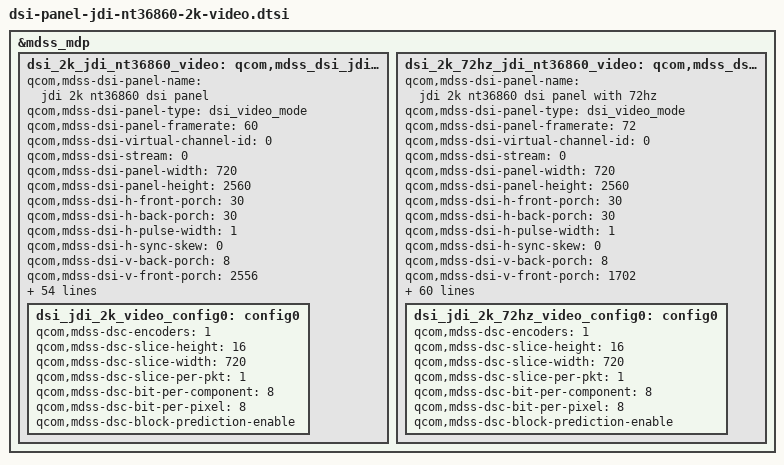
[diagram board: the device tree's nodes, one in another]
/* Copyright (c) 2017, Oculus VR.  All rights reserved.
 *
 * This program is free software; you can redistribute it and/or modify
 * it under the terms of the GNU General Public License version 2 and
 * only version 2 as published by the Free Software Foundation.
 *
 * This program is distributed in the hope that it will be useful,
 * but WITHOUT ANY WARRANTY; without even the implied warranty of
 * MERCHANTABILITY or FITNESS FOR A PARTICULAR PURPOSE.  See the
 * GNU General Public License for more details.
 */

&mdss_mdp {
	dsi_2k_jdi_nt36860_video: qcom,mdss_dsi_jdi_2k_nt36860_video {
		qcom,mdss-dsi-panel-name = "jdi 2k nt36860 dsi panel";
		qcom,mdss-dsi-panel-type = "dsi_video_mode";
		qcom,mdss-dsi-panel-framerate = <60>;
		qcom,mdss-dsi-virtual-channel-id = <0>;
		qcom,mdss-dsi-stream = <0>;
		qcom,mdss-dsi-panel-width = <720>;
		qcom,mdss-dsi-panel-height = <2560>;
		qcom,mdss-dsi-h-front-porch = <30>;
		qcom,mdss-dsi-h-back-porch = <30>;
		qcom,mdss-dsi-h-pulse-width = <1>;
		qcom,mdss-dsi-h-sync-skew = <0>;
		qcom,mdss-dsi-v-back-porch = <8>;
		qcom,mdss-dsi-v-front-porch = <2556>;
		qcom,mdss-dsi-v-pulse-width = <2>;
		qcom,mdss-dsi-bpp = <24>;
		qcom,mdss-dsi-border-color = <0>;
		qcom,mdss-dsi-on-command-state = "dsi_lp_mode";
		qcom,mdss-dsi-off-command-state = "dsi_hs_mode";
		qcom,mdss-dsi-h-sync-pulse = <0>;
		qcom,mdss-dsi-traffic-mode = "burst_mode";
		qcom,mdss-dsi-bllp-eof-power-mode;
		qcom,mdss-dsi-bllp-power-mode;
		qcom,mdss-dsi-lane-0-state;
		qcom,mdss-dsi-lane-1-state;
		qcom,mdss-dsi-lane-2-state;
		qcom,mdss-dsi-lane-3-state;
		qcom,mdss-dsi-panel-timings = [
			94 20 14 00 46 4a 1a 24 18 03 04 00
		];
		qcom,mdss-dsi-t-clk-post = <0xd>;
		qcom,mdss-dsi-t-clk-pre = <0x2e>;
		qcom,mdss-dsi-dma-trigger = "trigger_sw";
		qcom,mdss-dsi-mdp-trigger = "none";
		qcom,mdss-dsi-reset-sequence = <0 10>, <1 20>, <0 20>, <1 20>;
		qcom,mdss-dsi-te-pin-select = <1>;
		qcom,mdss-dsi-wr-mem-start = <0x2c>;
		qcom,mdss-dsi-wr-mem-continue = <0x3c>;
		qcom,mdss-dsi-te-dcs-command = <1>;
		qcom,mdss-dsi-te-check-enable;
		qcom,mdss-dsi-te-using-te-pin;
		qcom,ulps-enabled;
		qcom,dcs-cmd-by-left;
		qcom,mdss-dsi-tx-eot-append;
		qcom,mdss-pan-physical-width-dimension = <68>;
		qcom,mdss-pan-physical-height-dimension = <121>;

		qcom,mdss-dsi-panel-hdr-enabled;
		// Scale by 1 / 50000 to get x & y coordinates
		qcom,mdss-dsi-panel-hdr-color-primaries = <
			14700 15700 // W - x: 0.294, y: 0.314
			32000 16600 // R - x: 0.640, y: 0.332
			15000 30000 // G - x: 0.300. y: 0.600
			7700 3000>; // B - x: 0.154, y: 0.060
		// Scale by 1 / 10000 to get nits
		qcom,mdss-dsi-panel-peak-brightness = <1000000>;
		qcom,mdss-dsi-panel-blackness-level = <1400>;

		// Default to 10% base DC
		oculus,bklt-duty-cycle-numerator = <1000>;
		oculus,bklt-duty-cycle-denominator = <10000>;

		qcom,adjust-timer-wakeup-ms = <1>;
		qcom,mdss-dsi-panel-status-command = [
			06 01 00 01 05 00 02 0A 08
		];
		qcom,mdss-dsi-panel-status-command-state = "dsi_hs_mode";
		qcom,mdss-dsi-panel-status-check-mode = "reg_read";
		qcom,mdss-dsi-panel-status-value = <0x9c>;
		/*qcom,esd-check-enabled;*/
		qcom,mdss-dsi-panel-status-read-length=<1>;
		qcom,mdss-dsi-on-command = [
			15 01 00 00 00 00 02 ff 10
			15 01 00 00 00 00 02 fb 01
			39 01 00 00 00 00 05 2a 00 00 05 9f
			39 01 00 00 00 00 05 2b 00 00 09 ff
			15 01 00 00 00 00 02 35 00
			15 01 00 00 00 00 02 ba 03
			15 01 00 00 00 00 02 bb 03
			15 01 00 00 00 00 02 e5 00

			15 01 00 00 00 00 02 ff 24
			15 01 00 00 00 00 02 fb 01
			15 01 00 00 00 00 02 6f 9d
			15 01 00 00 00 00 02 70 d1
			15 01 00 00 00 00 02 f5 8e

			15 01 00 00 00 00 02 ff 25
			15 01 00 00 00 00 02 fb 01
			15 01 00 00 00 00 02 62 60
			15 01 00 00 00 00 02 65 02
			15 01 00 00 00 00 02 66 3e
			15 01 00 00 00 00 02 67 81
			15 01 00 00 00 00 02 c4 10

			15 01 00 00 00 00 02 ff 29
			15 01 00 00 00 00 02 fb 01
			15 01 00 00 00 00 02 43 68
			15 01 00 00 00 00 02 46 a0
			15 01 00 00 00 00 02 47 00
			15 01 00 00 00 00 02 48 ff
			15 01 00 00 00 00 02 49 02
			15 01 00 00 00 00 02 4a c0
			15 01 00 00 00 00 02 5a 32
			15 01 00 00 00 00 02 5b 32
			15 01 00 00 00 00 02 5c 32
			15 01 00 00 00 00 02 5d 32
			15 01 00 00 00 00 02 66 63
			15 01 00 00 00 00 02 68 63
			15 01 00 00 00 00 02 73 53
			15 01 00 00 00 00 02 75 53
			15 01 00 00 00 00 02 a9 06
			15 01 00 00 00 00 02 ab 77
			15 01 00 00 00 00 02 ad 06
			15 01 00 00 00 00 02 af 77
			15 01 00 00 00 00 02 b5 65

			15 01 00 00 00 00 02 ff d0
			15 01 00 00 00 00 02 fb 01
			15 01 00 00 00 00 02 05 88

			15 01 00 00 00 00 02 ff 10
			15 01 00 00 00 00 02 fb 01
			15 01 00 00 00 00 02 c0 83
			39 01 00 00 00 00 05 be 00 0a 09 fc

			05 01 00 00 78 00 01 11 /* sleep out + delay 120ms */
			05 01 00 00 28 00 01 29 /* display on + delay 120ms */
			07 01 00 00 0a 00 02 01 00
		];

		qcom,mdss-dsi-off-command = [
			05 01 00 00 78 00 02 28 00
			05 01 00 00 78 00 02 34 00
			05 01 00 00 78 00 02 10 00
		];

		qcom,compression-mode = "dsc";
		qcom,config-select = <&dsi_jdi_2k_video_config0>;

		dsi_jdi_2k_video_config0: config0 {
			qcom,mdss-dsc-encoders = <1>;
			qcom,mdss-dsc-slice-height = <16>;
			qcom,mdss-dsc-slice-width = <720>;
			qcom,mdss-dsc-slice-per-pkt = <1>;
			qcom,mdss-dsc-bit-per-component = <8>;
			qcom,mdss-dsc-bit-per-pixel = <8>;
			qcom,mdss-dsc-block-prediction-enable;
		};
	};

	dsi_2k_72hz_jdi_nt36860_video: qcom,mdss_dsi_jdi_2k_72hz_nt36860_video {
		qcom,mdss-dsi-panel-name = "jdi 2k nt36860 dsi panel with 72hz";
		qcom,mdss-dsi-panel-type = "dsi_video_mode";
		qcom,mdss-dsi-panel-framerate = <72>;
		qcom,mdss-dsi-virtual-channel-id = <0>;
		qcom,mdss-dsi-stream = <0>;
		qcom,mdss-dsi-panel-width = <720>;
		qcom,mdss-dsi-panel-height = <2560>;
		qcom,mdss-dsi-h-front-porch = <30>;
		qcom,mdss-dsi-h-back-porch = <30>;
		qcom,mdss-dsi-h-pulse-width = <1>;
		qcom,mdss-dsi-h-sync-skew = <0>;
		qcom,mdss-dsi-v-back-porch = <8>;
		qcom,mdss-dsi-v-front-porch = <1702>;
		qcom,mdss-dsi-v-pulse-width = <2>;
		qcom,mdss-dsi-bpp = <24>;
		qcom,mdss-dsi-border-color = <0>;
		qcom,mdss-dsi-on-command-state = "dsi_lp_mode";
		qcom,mdss-dsi-off-command-state = "dsi_hs_mode";
		qcom,mdss-dsi-h-sync-pulse = <0>;
		qcom,mdss-dsi-traffic-mode = "burst_mode";
		qcom,mdss-dsi-bllp-eof-power-mode;
		qcom,mdss-dsi-bllp-power-mode;
		qcom,mdss-dsi-lane-0-state;
		qcom,mdss-dsi-lane-1-state;
		qcom,mdss-dsi-lane-2-state;
		qcom,mdss-dsi-lane-3-state;
		qcom,mdss-dsi-panel-timings = [
			94 20 14 00 46 4a 1a 24 18 03 04 00
		];
		qcom,mdss-dsi-t-clk-post = <0xd>;
		qcom,mdss-dsi-t-clk-pre = <0x2e>;
		qcom,mdss-dsi-dma-trigger = "trigger_sw";
		qcom,mdss-dsi-mdp-trigger = "none";
		qcom,mdss-dsi-reset-sequence = <1 20>, <0 20>, <1 20>;
		qcom,mdss-dsi-te-pin-select = <1>;
		qcom,mdss-dsi-wr-mem-start = <0x2c>;
		qcom,mdss-dsi-wr-mem-continue = <0x3c>;
		qcom,mdss-dsi-te-dcs-command = <1>;
		qcom,mdss-dsi-te-check-enable;
		qcom,mdss-dsi-te-using-te-pin;
		qcom,ulps-enabled;
		qcom,dcs-cmd-by-left;
		qcom,mdss-dsi-tx-eot-append;
		qcom,mdss-pan-physical-width-dimension = <68>;
		qcom,mdss-pan-physical-height-dimension = <121>;

		qcom,mdss-dsi-panel-hdr-enabled;
		// Scale by 1 / 50000 to get x & y coordinates
		qcom,mdss-dsi-panel-hdr-color-primaries = <
			14700 15700 // W - x: 0.294, y: 0.314
			32000 16600 // R - x: 0.640, y: 0.332
			15000 30000 // G - x: 0.300. y: 0.600
			7700 3000>; // B - x: 0.154, y: 0.060
		// Scale by 1 / 10000 to get nits
		qcom,mdss-dsi-panel-peak-brightness = <1000000>;
		qcom,mdss-dsi-panel-blackness-level = <1400>;

		// Default to 10% base DC
		oculus,bklt-duty-cycle-numerator = <1000>;
		oculus,bklt-duty-cycle-denominator = <10000>;

		qcom,adjust-timer-wakeup-ms = <1>;
		qcom,mdss-dsi-panel-status-command = [
			06 01 00 01 05 00 02 0A 08
		];
		qcom,mdss-dsi-panel-status-command-state = "dsi_hs_mode";
		qcom,mdss-dsi-panel-status-check-mode = "reg_read";
		qcom,mdss-dsi-panel-status-value = <0x9c>;
		/*qcom,esd-check-enabled;*/
		qcom,mdss-dsi-panel-status-read-length=<1>;
		qcom,mdss-dsi-on-command = [
			15 01 00 00 00 00 02 ff 10
			15 01 00 00 00 00 02 fb 01
			39 01 00 00 00 00 05 2a 00 00 05 9f
			39 01 00 00 00 00 05 2b 00 00 09 ff
			15 01 00 00 00 00 02 35 00
			15 01 00 00 00 00 02 ba 03
			15 01 00 00 00 00 02 bb 03
			15 01 00 00 00 00 02 e5 00

			15 01 00 00 00 00 02 ff 24
			15 01 00 00 00 00 02 fb 01
			15 01 00 00 00 00 02 6f 9d
			15 01 00 00 00 00 02 70 d1
			15 01 00 00 00 00 02 f5 8e

			15 01 00 00 00 00 02 ff 25
			15 01 00 00 00 00 02 fb 01
			15 01 00 00 00 00 02 62 60
			15 01 00 00 00 00 02 65 01
			15 01 00 00 00 00 02 66 de
			15 01 00 00 00 00 02 67 6b
			15 01 00 00 00 00 02 c4 10

			15 01 00 00 00 00 02 ff 29
			15 01 00 00 00 00 02 fb 01
			15 01 00 00 00 00 02 43 68
			15 01 00 00 00 00 02 46 a0
			15 01 00 00 00 00 02 47 00
			15 01 00 00 00 00 02 48 ff
			15 01 00 00 00 00 02 49 02
			15 01 00 00 00 00 02 4a c0
			15 01 00 00 00 00 02 5a 32
			15 01 00 00 00 00 02 5b 32
			15 01 00 00 00 00 02 5c 32
			15 01 00 00 00 00 02 5d 32
			15 01 00 00 00 00 02 66 63
			15 01 00 00 00 00 02 68 63
			15 01 00 00 00 00 02 73 53
			15 01 00 00 00 00 02 75 53
			15 01 00 00 00 00 02 a9 06
			15 01 00 00 00 00 02 ab 77
			15 01 00 00 00 00 02 ad 06
			15 01 00 00 00 00 02 af 77
			15 01 00 00 00 00 02 b5 65

			15 01 00 00 00 00 02 ff d0
			15 01 00 00 00 00 02 fb 01
			15 01 00 00 00 00 02 05 88

			15 01 00 00 00 00 02 ff 10
			15 01 00 00 00 00 02 fb 01
			15 01 00 00 00 00 02 c0 83
			39 01 00 00 00 00 05 be 00 0a 06 a6

			05 01 00 00 78 00 01 11 /* sleep out + delay 120ms */
			05 01 00 00 28 00 01 29 /* display on + delay 120ms */
			07 01 00 00 0a 00 02 01 00
		];

		qcom,mdss-dsi-off-command = [
			05 01 00 00 78 00 02 28 00
			05 01 00 00 78 00 02 34 00
			05 01 00 00 78 00 02 10 00
		];

		qcom,compression-mode = "dsc";
		qcom,config-select = <&dsi_jdi_2k_72hz_video_config0>;

		qcom,mdss-dsi-pan-enable-dynamic-fps;
		qcom,mdss-dsi-pan-disable-early-wakeup-dfps-update;
		qcom,mdss-dsi-pan-fps-update = "dfps_immediate_porch_mode_vfp";
		qcom,mdss-dsi-min-refresh-rate = <60>;
		qcom,mdss-dsi-max-refresh-rate = <72>;

		dsi_jdi_2k_72hz_video_config0: config0 {
			qcom,mdss-dsc-encoders = <1>;
			qcom,mdss-dsc-slice-height = <16>;
			qcom,mdss-dsc-slice-width = <720>;
			qcom,mdss-dsc-slice-per-pkt = <1>;
			qcom,mdss-dsc-bit-per-component = <8>;
			qcom,mdss-dsc-bit-per-pixel = <8>;
			qcom,mdss-dsc-block-prediction-enable;
		};
	};
};
